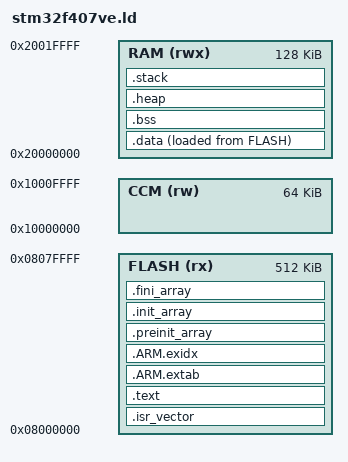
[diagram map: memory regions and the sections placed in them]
ENTRY(Reset_Handler)

MEMORY
{
    FLASH (rx) : ORIGIN = 0x08000000, LENGTH = 512K
    RAM (rwx) : ORIGIN = 0x20000000, LENGTH = 128K
    CCM (rw) : ORIGIN = 0x10000000, LENGTH = 64K
}

_estack = ORIGIN(RAM) + LENGTH(RAM);
_stack_limit = _estack - 8K;

SECTIONS
{
    .isr_vector :
    {
        . = ALIGN(4);
        KEEP(*(.isr_vector))
        . = ALIGN(4);
    } > FLASH

    .text :
    {
        . = ALIGN(4);
        *(.text .text.*)
        *(.rodata .rodata.*)
        KEEP(*(.firmware_signature))
        KEEP(*(.init))
        KEEP(*(.fini))
        . = ALIGN(4);
    } > FLASH

    .ARM.extab : { *(.ARM.extab* .gnu.linkonce.armextab.*) } > FLASH
    .ARM.exidx :
    {
        __exidx_start = .;
        *(.ARM.exidx* .gnu.linkonce.armexidx.*)
        __exidx_end = .;
    } > FLASH

    .preinit_array :
    {
        PROVIDE_HIDDEN(__preinit_array_start = .);
        KEEP(*(.preinit_array*))
        PROVIDE_HIDDEN(__preinit_array_end = .);
    } > FLASH
    .init_array :
    {
        PROVIDE_HIDDEN(__init_array_start = .);
        KEEP(*(SORT(.init_array.*)))
        KEEP(*(.init_array*))
        PROVIDE_HIDDEN(__init_array_end = .);
    } > FLASH
    .fini_array :
    {
        PROVIDE_HIDDEN(__fini_array_start = .);
        KEEP(*(SORT(.fini_array.*)))
        KEEP(*(.fini_array*))
        PROVIDE_HIDDEN(__fini_array_end = .);
    } > FLASH

    _sidata = LOADADDR(.data);
    .data :
    {
        . = ALIGN(4);
        _sdata = .;
        *(.data .data.*)
        . = ALIGN(4);
        _edata = .;
    } > RAM AT > FLASH

    .bss (NOLOAD) :
    {
        . = ALIGN(8);
        _sbss = .;
        *(.bss .bss.*)
        *(COMMON)
        . = ALIGN(8);
        _ebss = .;
    } > RAM

    .heap (NOLOAD) :
    {
        . = ALIGN(8);
        _heap_start = .;
        . += 4K;
        _heap_end = .;
    } > RAM

    .stack _stack_limit (NOLOAD) :
    {
        . += 8K;
    } > RAM

    .ARM.attributes 0 : { *(.ARM.attributes) }
    /DISCARD/ : { *(.note.GNU-stack) *(.comment) }
}

ASSERT(_heap_end <= _stack_limit, "SRAM sections overlap the main stack")
